VERSION ""

NS_ :

BS_:

BU_: ESP PDM C50 ATCCR ATCCF

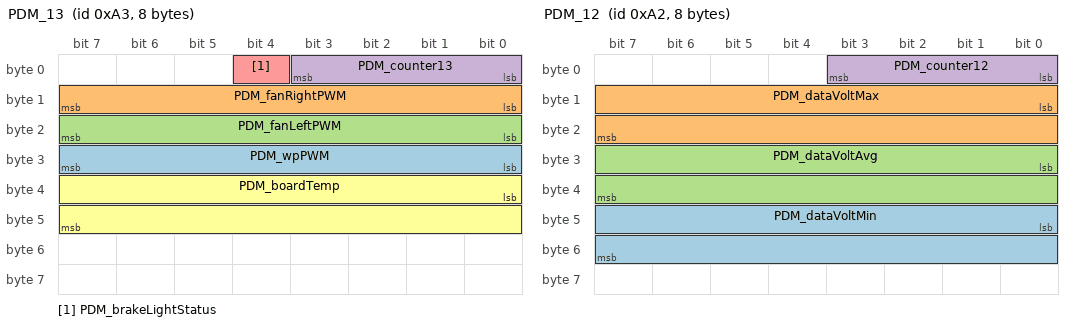
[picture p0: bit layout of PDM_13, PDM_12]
BO_ 163 PDM_13: 8 PDM
 SG_ PDM_wpPWM : 24|8@1+ (1,0) [0|255] "" Vector__XXX
 SG_ PDM_fanRightPWM : 8|8@1+ (1,0) [0|255] "" Vector__XXX
 SG_ PDM_fanLeftPWM : 16|8@1+ (1,0) [0|255] "" Vector__XXX
 SG_ PDM_counter13 : 0|4@1+ (1,0) [0|0] "" Vector__XXX
 SG_ PDM_brakeLightStatus : 4|1@1+ (1,0) [0|1] "" Vector__XXX
 SG_ PDM_boardTemp : 32|16@1- (0.1,0) [-3276.8|3276.7] "C" Vector__XXX

BO_ 162 PDM_12: 8 PDM
 SG_ PDM_dataVoltMin : 40|16@1- (0.001,0) [-32.768|32.767] "V" Vector__XXX
 SG_ PDM_dataVoltMax : 8|16@1- (0.001,0) [-32.768|32.767] "V" Vector__XXX
 SG_ PDM_dataVoltAvg : 24|16@1- (0.001,0) [-32.768|32.767] "V" Vector__XXX
 SG_ PDM_counter12 : 0|4@1+ (1,0) [0|0] "" Vector__XXX

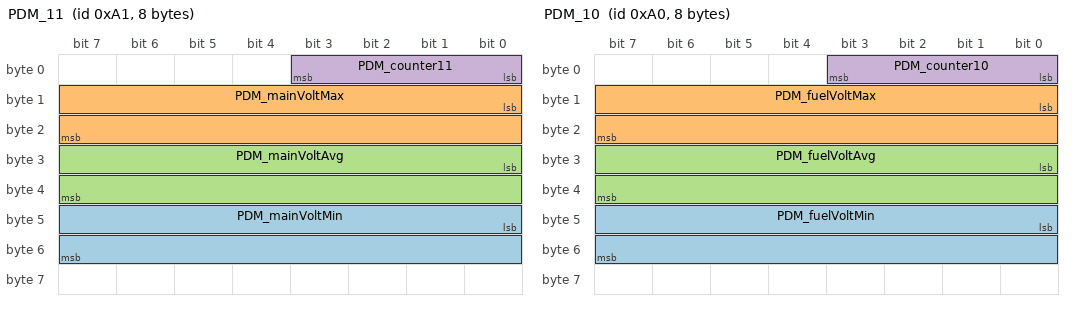
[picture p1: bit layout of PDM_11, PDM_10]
BO_ 161 PDM_11: 8 PDM
 SG_ PDM_mainVoltMin : 40|16@1- (0.001,0) [-32.768|32.767] "V" Vector__XXX
 SG_ PDM_mainVoltMax : 8|16@1- (0.001,0) [-32.768|32.767] "V" Vector__XXX
 SG_ PDM_mainVoltAvg : 24|16@1- (0.001,0) [-32.768|32.767] "V" Vector__XXX
 SG_ PDM_counter11 : 0|4@1+ (1,0) [0|0] "" Vector__XXX

BO_ 160 PDM_10: 8 PDM
 SG_ PDM_fuelVoltMin : 40|16@1- (0.001,0) [-32.768|32.767] "V" Vector__XXX
 SG_ PDM_fuelVoltMax : 8|16@1- (0.001,0) [-32.768|32.767] "V" Vector__XXX
 SG_ PDM_fuelVoltAvg : 24|16@1- (0.001,0) [-32.768|32.767] "V" Vector__XXX
 SG_ PDM_counter10 : 0|4@1+ (1,0) [0|0] "" Vector__XXX

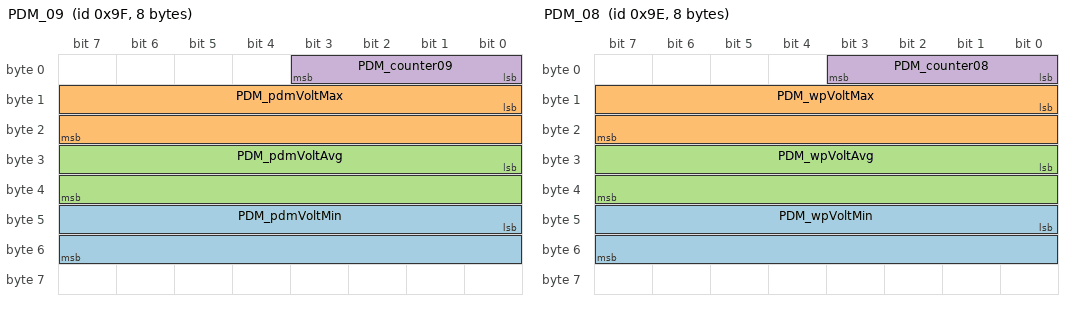
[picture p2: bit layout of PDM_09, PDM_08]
BO_ 159 PDM_09: 8 PDM
 SG_ PDM_pdmVoltMin : 40|16@1- (0.001,0) [-32.768|32.767] "V" Vector__XXX
 SG_ PDM_pdmVoltMax : 8|16@1- (0.001,0) [-32.768|32.767] "V" Vector__XXX
 SG_ PDM_pdmVoltAvg : 24|16@1- (0.001,0) [-32.768|32.767] "V" Vector__XXX
 SG_ PDM_counter09 : 0|4@1+ (1,0) [0|0] "" Vector__XXX

BO_ 158 PDM_08: 8 PDM
 SG_ PDM_wpVoltMin : 40|16@1- (0.001,0) [-32.768|32.767] "V" Vector__XXX
 SG_ PDM_wpVoltMax : 8|16@1- (0.001,0) [-32.768|32.767] "V" Vector__XXX
 SG_ PDM_wpVoltAvg : 24|16@1- (0.001,0) [-32.768|32.767] "V" Vector__XXX
 SG_ PDM_counter08 : 0|4@1+ (1,0) [0|0] "" Vector__XXX

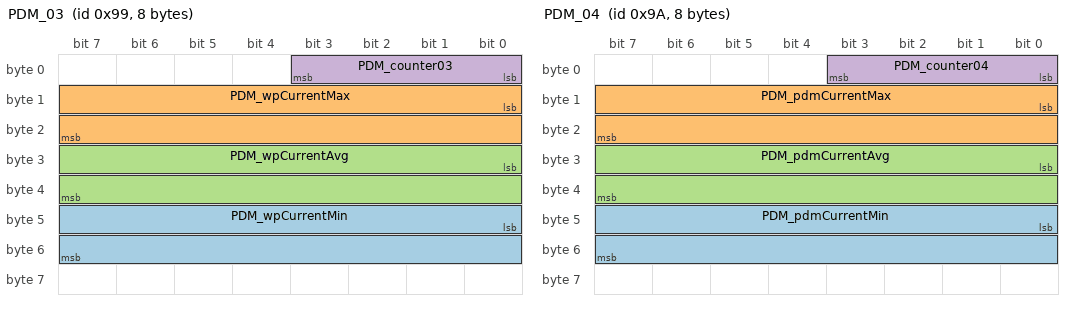
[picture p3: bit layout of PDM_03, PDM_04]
BO_ 153 PDM_03: 8 PDM
 SG_ PDM_wpCurrentMin : 40|16@1- (0.01,0) [-327.68|327.67] "A" Vector__XXX
 SG_ PDM_wpCurrentMax : 8|16@1- (0.01,0) [-327.68|327.67] "A" Vector__XXX
 SG_ PDM_wpCurrentAvg : 24|16@1- (0.01,0) [-327.68|327.67] "A" Vector__XXX
 SG_ PDM_counter03 : 0|4@1+ (1,0) [0|15] "" Vector__XXX

BO_ 154 PDM_04: 8 PDM
 SG_ PDM_pdmCurrentMin : 40|16@1- (0.01,0) [-327.68|327.67] "A" Vector__XXX
 SG_ PDM_pdmCurrentMax : 8|16@1- (0.01,0) [-327.68|327.67] "A" Vector__XXX
 SG_ PDM_pdmCurrentAvg : 24|16@1- (0.01,0) [-327.68|327.67] "A" Vector__XXX
 SG_ PDM_counter04 : 0|4@1+ (1,0) [0|0] "" Vector__XXX

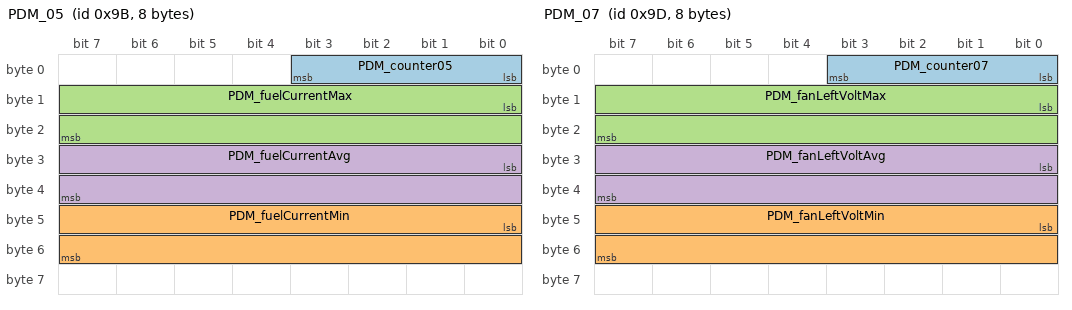
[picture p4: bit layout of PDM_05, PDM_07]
BO_ 155 PDM_05: 8 PDM
 SG_ PDM_counter05 : 0|4@1+ (1,0) [0|0] "" Vector__XXX
 SG_ PDM_fuelCurrentMin : 40|16@1- (0.01,0) [-327.68|327.67] "A" Vector__XXX
 SG_ PDM_fuelCurrentMax : 8|16@1- (0.01,0) [-327.68|327.67] "A" Vector__XXX
 SG_ PDM_fuelCurrentAvg : 24|16@1- (0.01,0) [-327.68|327.67] "A" Vector__XXX

BO_ 157 PDM_07: 8 PDM
 SG_ PDM_counter07 : 0|4@1+ (1,0) [0|0] "" Vector__XXX
 SG_ PDM_fanLeftVoltMin : 40|16@1- (0.001,0) [-32.768|32.767] "V" Vector__XXX
 SG_ PDM_fanLeftVoltMax : 8|16@1- (0.001,0) [-32.768|32.767] "V" Vector__XXX
 SG_ PDM_fanLeftVoltAvg : 24|16@1- (0.001,0) [-32.768|32.767] "V" Vector__XXX

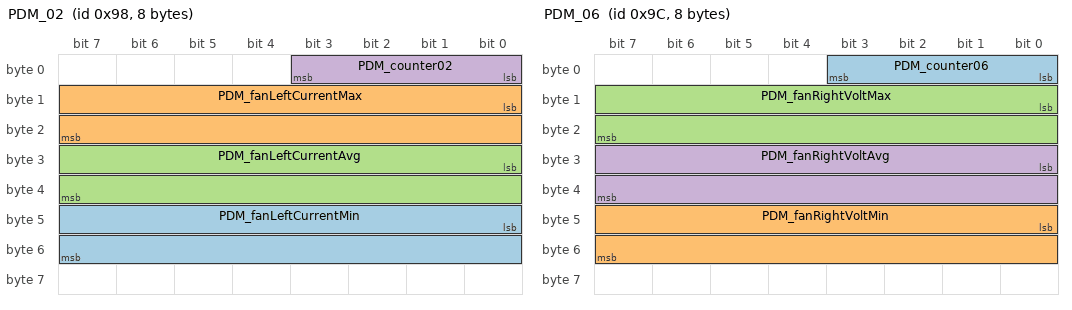
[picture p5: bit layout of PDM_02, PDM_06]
BO_ 152 PDM_02: 8 PDM
 SG_ PDM_fanLeftCurrentMin : 40|16@1- (0.01,0) [-327.68|327.67] "A" Vector__XXX
 SG_ PDM_fanLeftCurrentMax : 8|16@1- (0.01,0) [-327.68|327.67] "A" Vector__XXX
 SG_ PDM_fanLeftCurrentAvg : 24|16@1- (0.01,0) [-327.68|327.67] "A" Vector__XXX
 SG_ PDM_counter02 : 0|4@1+ (1,0) [0|15] "" Vector__XXX

BO_ 156 PDM_06: 8 PDM
 SG_ PDM_counter06 : 0|4@1+ (1,0) [0|0] "" Vector__XXX
 SG_ PDM_fanRightVoltMin : 40|16@1- (0.001,0) [-32.768|32.767] "V" Vector__XXX
 SG_ PDM_fanRightVoltMax : 8|16@1- (0.001,0) [-32.768|32.767] "V" Vector__XXX
 SG_ PDM_fanRightVoltAvg : 24|16@1- (0.001,0) [-32.768|32.767] "V" Vector__XXX

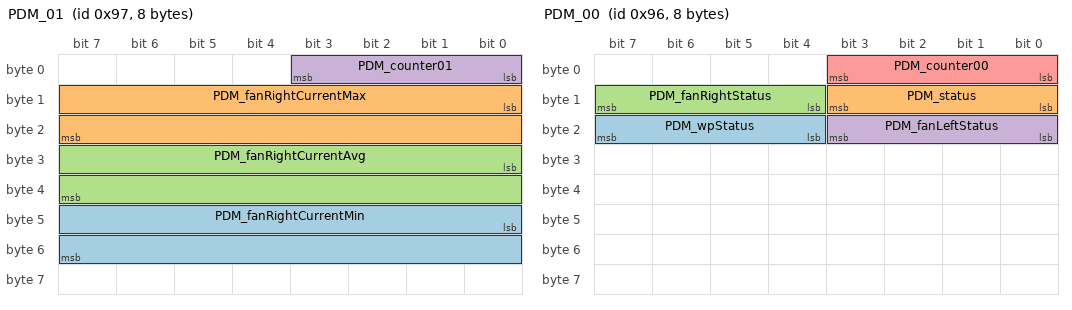
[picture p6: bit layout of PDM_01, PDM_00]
BO_ 151 PDM_01: 8 PDM
 SG_ PDM_fanRightCurrentMin : 40|16@1- (0.01,0) [-327.68|327.67] "A" Vector__XXX
 SG_ PDM_fanRightCurrentMax : 8|16@1- (0.01,0) [-327.68|327.67] "A" Vector__XXX
 SG_ PDM_fanRightCurrentAvg : 24|16@1- (0.01,0) [-327.68|327.67] "A" Vector__XXX
 SG_ PDM_counter01 : 0|4@1+ (1,0) [0|15] "" Vector__XXX

BO_ 150 PDM_00: 8 PDM
 SG_ PDM_wpStatus : 20|4@1+ (1,0) [0|15] "" Vector__XXX
 SG_ PDM_status : 8|4@1+ (1,0) [0|15] "" Vector__XXX
 SG_ PDM_fanRightStatus : 12|4@1+ (1,0) [0|15] "" Vector__XXX
 SG_ PDM_fanLeftStatus : 16|4@1+ (1,0) [0|15] "" Vector__XXX
 SG_ PDM_counter00 : 0|4@1+ (1,0) [0|15] "" Vector__XXX

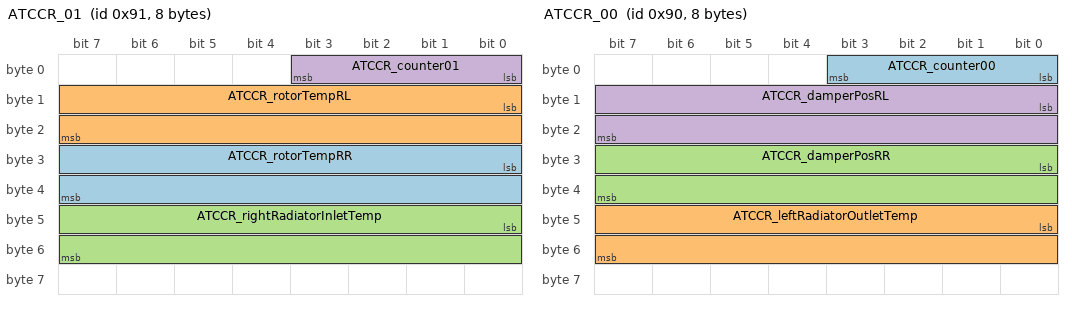
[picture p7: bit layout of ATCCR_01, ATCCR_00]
BO_ 145 ATCCR_01: 8 ATCCR
 SG_ ATCCR_rotorTempRR : 24|16@1- (1,0) [0|0] "" Vector__XXX
 SG_ ATCCR_rotorTempRL : 8|16@1- (1,0) [0|0] "" Vector__XXX
 SG_ ATCCR_rightRadiatorInletTemp : 40|16@1- (1,0) [0|0] "" Vector__XXX
 SG_ ATCCR_counter01 : 0|4@1+ (1,0) [0|0] "" Vector__XXX

BO_ 144 ATCCR_00: 8 ATCCR
 SG_ ATCCR_counter00 : 0|4@1- (1,0) [0|0] "" Vector__XXX
 SG_ ATCCR_leftRadiatorOutletTemp : 40|16@1- (1,0) [0|0] "" Vector__XXX
 SG_ ATCCR_damperPosRR : 24|16@1- (1,0) [0|0] "" Vector__XXX
 SG_ ATCCR_damperPosRL : 8|16@1- (1,0) [0|0] "" Vector__XXX

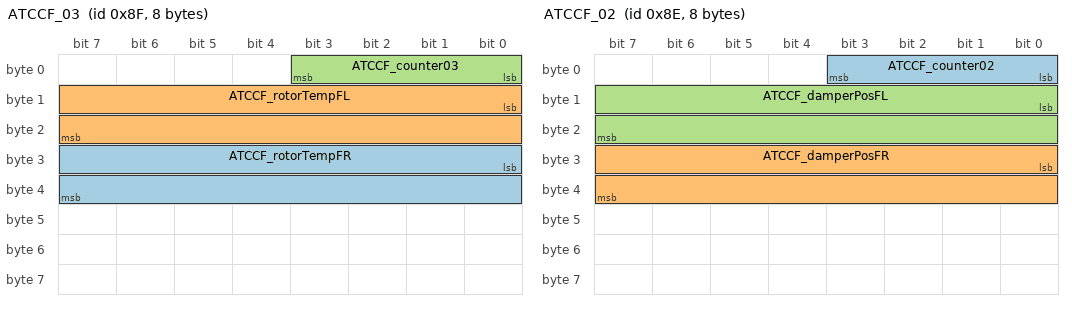
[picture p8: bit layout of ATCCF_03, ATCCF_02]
BO_ 143 ATCCF_03: 8 ATCCF
 SG_ ATCCF_rotorTempFR : 24|16@1- (0.1,0) [-3276.8|3276.7] "" Vector__XXX
 SG_ ATCCF_rotorTempFL : 8|16@1- (0.1,0) [-3276.8|3276.7] "" Vector__XXX
 SG_ ATCCF_counter03 : 0|4@1+ (1,0) [0|0] "" Vector__XXX

BO_ 142 ATCCF_02: 8 ATCCF
 SG_ ATCCF_counter02 : 0|4@1+ (1,0) [0|15] "" Vector__XXX
 SG_ ATCCF_damperPosFR : 24|16@1- (0.1,0) [-3276.8|3276.7] "" Vector__XXX
 SG_ ATCCF_damperPosFL : 8|16@1- (0.1,0) [-3276.8|3276.7] "" Vector__XXX

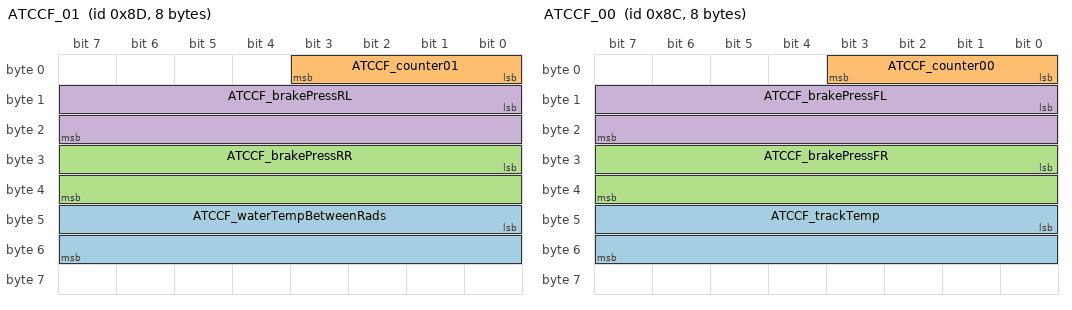
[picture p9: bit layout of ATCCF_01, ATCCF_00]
BO_ 141 ATCCF_01: 8 ATCCF
 SG_ ATCCF_waterTempBetweenRads : 40|16@1- (0.1,0) [-3276.8|3276.7] "" Vector__XXX
 SG_ ATCCF_counter01 : 0|4@1+ (1,0) [0|15] "" Vector__XXX
 SG_ ATCCF_brakePressRR : 24|16@1- (0.1,0) [-3276.8|3276.7] "" Vector__XXX
 SG_ ATCCF_brakePressRL : 8|16@1- (0.1,0) [-3276.8|3276.7] "" Vector__XXX

BO_ 140 ATCCF_00: 8 ATCCF
 SG_ ATCCF_trackTemp : 40|16@1- (0.1,0) [-3276.8|3276.7] "" Vector__XXX
 SG_ ATCCF_counter00 : 0|4@1+ (1,0) [0|15] "" Vector__XXX
 SG_ ATCCF_brakePressFR : 24|16@1- (0.1,0) [-3276.8|3276.7] "" Vector__XXX
 SG_ ATCCF_brakePressFL : 8|16@1- (0.1,0) [-3276.8|3276.7] "" Vector__XXX

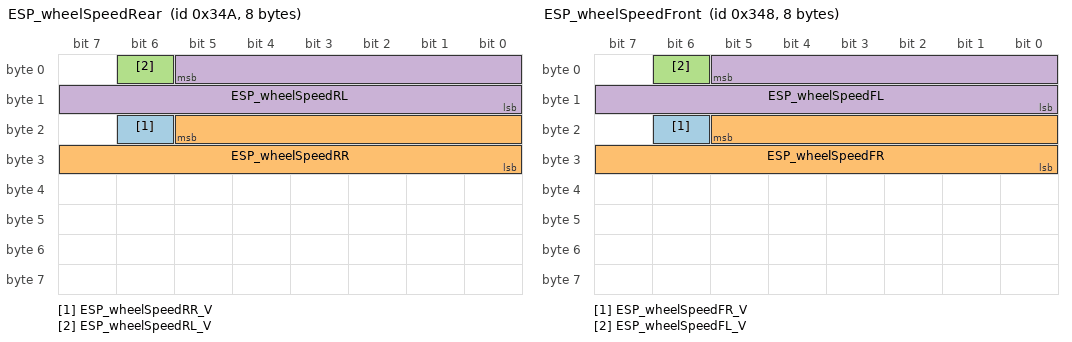
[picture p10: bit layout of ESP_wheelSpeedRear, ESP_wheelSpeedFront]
BO_ 842 ESP_wheelSpeedRear: 8 ESP
 SG_ ESP_wheelSpeedRR_V : 22|1@0+ (1,0) [0|1] "" Vector__XXX
 SG_ ESP_wheelSpeedRR : 21|14@0+ (0.0194178,0) [0|318.1218174] "" Vector__XXX
 SG_ ESP_wheelSpeedRL_V : 6|1@0+ (1,0) [0|1] "" Vector__XXX
 SG_ ESP_wheelSpeedRL : 5|14@0+ (0.0194178,0) [0|318.1218174] "" Vector__XXX

BO_ 840 ESP_wheelSpeedFront: 8 ESP
 SG_ ESP_wheelSpeedFR_V : 22|1@0+ (1,0) [0|1] "" Vector__XXX
 SG_ ESP_wheelSpeedFR : 21|14@0+ (0.0194178,0) [0|318.1218174] "" Vector__XXX
 SG_ ESP_wheelSpeedFL_V : 6|1@0+ (1,0) [0|1] "" Vector__XXX
 SG_ ESP_wheelSpeedFL : 5|14@0+ (0.0194178,0) [0|318.1218174] "" Vector__XXX

CM_ BU_ ESP "Bosch ESP Unit";
CM_ BU_ PDM "Power Distrubution Module";
CM_ BU_ C50 "C50 Data Logger";
CM_ BU_ ATCCR "The Rear Analog To CAN Converter";
CM_ BU_ ATCCF "Front Analog To CAN Converter";
CM_ SG_ 163 PDM_wpPWM "The PWM rate of the waterpump";
CM_ SG_ 163 PDM_fanRightPWM "PWM rate of the right fan";
CM_ SG_ 163 PDM_fanLeftPWM "PWM rate of the right fan";
CM_ SG_ 163 PDM_brakeLightStatus "State of the brake light
0 = Off
1 = On";
CM_ SG_ 163 PDM_boardTemp "PDM board temperature";
CM_ SG_ 162 PDM_dataVoltMin "voltage of the data circuit";
CM_ SG_ 162 PDM_dataVoltMax "voltage of the data circuit";
CM_ SG_ 162 PDM_dataVoltAvg "voltage of the data circuit";
CM_ SG_ 161 PDM_mainVoltMin "voltage of the main circuit";
CM_ SG_ 161 PDM_mainVoltMax "voltage of the main circuit";
CM_ SG_ 161 PDM_mainVoltAvg "voltage of the main circuit";
CM_ SG_ 160 PDM_fuelVoltMin "voltage of the fuel circuit";
CM_ SG_ 160 PDM_fuelVoltMax "voltage of the fuel circuit";
CM_ SG_ 160 PDM_fuelVoltAvg "voltage of the fuel circuit";
CM_ SG_ 159 PDM_pdmVoltMin "voltage of the PDM";
CM_ SG_ 159 PDM_pdmVoltMax "voltage of the PDM";
CM_ SG_ 159 PDM_pdmVoltAvg "voltage of the PDM";
CM_ SG_ 158 PDM_wpVoltMin "the voltage of the water pump";
CM_ SG_ 158 PDM_wpVoltMax "the voltage of the water pump";
CM_ SG_ 158 PDM_wpVoltAvg "the voltage of the water pump";
CM_ SG_ 153 PDM_wpCurrentMin "the current going through the water pump";
CM_ SG_ 153 PDM_wpCurrentMax "the current going through the water pump";
CM_ SG_ 153 PDM_wpCurrentAvg "the current going through the water pump";
CM_ SG_ 154 PDM_pdmCurrentMin "the total current going through the PDM";
CM_ SG_ 154 PDM_pdmCurrentMax "the total current going through the PDM";
CM_ SG_ 154 PDM_pdmCurrentAvg "the total current going through the PDM";
CM_ SG_ 155 PDM_fuelCurrentMin "current through the fuel circuit";
CM_ SG_ 155 PDM_fuelCurrentMax "current through the fuel circuit";
CM_ SG_ 155 PDM_fuelCurrentAvg "current through the fuel circuit";
CM_ SG_ 157 PDM_fanLeftVoltMin "voltage of the left fan";
CM_ SG_ 157 PDM_fanLeftVoltMax "voltage of the left fan";
CM_ SG_ 157 PDM_fanLeftVoltAvg "voltage of the left fan";
CM_ SG_ 152 PDM_fanLeftCurrentMin "current of the left fan";
CM_ SG_ 152 PDM_fanLeftCurrentMax "current of the left fan";
CM_ SG_ 152 PDM_fanLeftCurrentAvg "current of the left fan";
CM_ SG_ 156 PDM_fanRightVoltMin "voltage of the right fan";
CM_ SG_ 156 PDM_fanRightVoltMax "voltage of the right fan";
CM_ SG_ 156 PDM_fanRightVoltAvg "voltage of the right fan";
CM_ SG_ 151 PDM_fanRightCurrentMin "current of the right fan";
CM_ SG_ 151 PDM_fanRightCurrentMax "current of the right fan";
CM_ SG_ 151 PDM_fanRightCurrentAvg "current of the right fan";
CM_ SG_ 150 PDM_wpStatus "status of the water pump";
CM_ SG_ 150 PDM_status "to be used to print error messages:

0 =
1 =
2 =
3 =
4 =
5 =
6 =
7 =
8 =
9 =
10 =
11 =
12 =
13 =
14 =
15 =  ";
CM_ SG_ 150 PDM_fanRightStatus "status of the right fan";
CM_ SG_ 150 PDM_fanLeftStatus "status of the left fan";
CM_ SG_ 145 ATCCR_rotorTempRR "rear right rotor temperature";
CM_ SG_ 145 ATCCR_rotorTempRL "rear left rotor temperature";
CM_ SG_ 145 ATCCR_rightRadiatorInletTemp "right radiator inlet temperature";
CM_ SG_ 144 ATCCR_leftRadiatorOutletTemp "left radiator outlet temperature";
CM_ SG_ 144 ATCCR_damperPosRR "rear right damper position";
CM_ SG_ 144 ATCCR_damperPosRL "rear left damper position";
CM_ SG_ 143 ATCCF_rotorTempFR "front right rotor temperature";
CM_ SG_ 143 ATCCF_rotorTempFL "front left rotor temperature";
CM_ SG_ 142 ATCCF_damperPosFR "front right damper position";
CM_ SG_ 142 ATCCF_damperPosFL "front left damper position";
CM_ SG_ 141 ATCCF_waterTempBetweenRads "water temperature between radiators";
CM_ SG_ 141 ATCCF_brakePressRR "rear right brake pressure";
CM_ SG_ 141 ATCCF_brakePressRL "rear left brake pressure";
CM_ SG_ 140 ATCCF_trackTemp "tack temperature";
CM_ SG_ 140 ATCCF_brakePressFR "front right brake pressure";
CM_ SG_ 140 ATCCF_brakePressFL "front left brake pressure";
BA_DEF_  "BusType" STRING ;
BA_DEF_DEF_  "BusType" "CAN";
